VERSION "created by canmatrix"

NS_ :

BS_:

BU_: User ADM_PC_LL25 ADM_PC_BC25 ADM_PC_BP25 ADM_PC_BI25

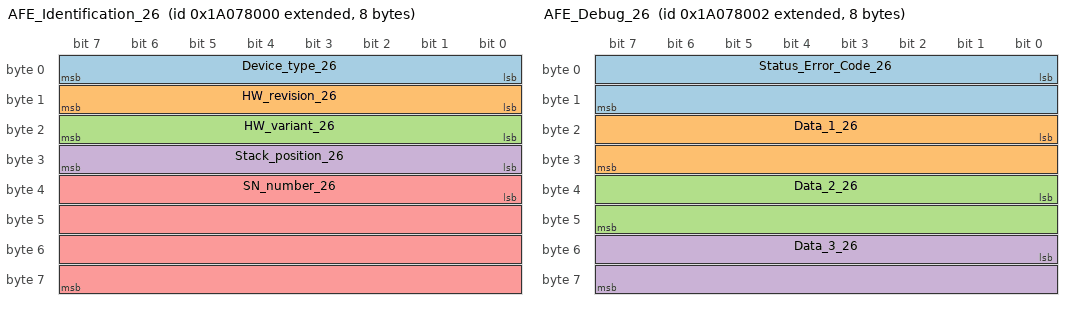
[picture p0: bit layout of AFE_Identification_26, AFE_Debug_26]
BO_ 2584182784 AFE_Identification_26: 8 ADM_PC_BP25
 SG_ Device_type_26 : 0|8@1+ (1,0) [0|255] "" Vector__XXX
 SG_ HW_revision_26 : 8|8@1+ (1,0) [0|255] "" Vector__XXX
 SG_ HW_variant_26 : 16|8@1+ (1,0) [0|255] "" Vector__XXX
 SG_ Stack_position_26 : 24|8@1+ (1,0) [0|255] "" Vector__XXX
 SG_ SN_number_26 : 32|32@1+ (1,0) [0|4294967295] "" Vector__XXX

BO_ 2584182785 AFE_FwInfo_26: 8 ADM_PC_BP25
 SG_ FW_info_mux_26 M : 56|8@1+ (1,0) [0|255] "" Vector__XXX
 SG_ FW_revision_0_26 m0 : 0|8@1+ (1,0) [0|255] "" Vector__XXX
 SG_ FW_revision_1_26 m0 : 8|8@1+ (1,0) [0|255] "" Vector__XXX
 SG_ FW_revision_2_26 m0 : 16|8@1+ (1,0) [0|255] "" Vector__XXX
 SG_ FW_revision_3_26 m0 : 24|8@1+ (1,0) [0|255] "" Vector__XXX
 SG_ FW_revision_4_26 m0 : 32|8@1+ (1,0) [0|255] "" Vector__XXX
 SG_ FW_revision_5_26 m0 : 40|8@1+ (1,0) [0|255] "" Vector__XXX
 SG_ FW_revision_6_26 m0 : 48|8@1+ (1,0) [0|255] "" Vector__XXX
 SG_ FW_revision_7_26 m1 : 0|8@1+ (1,0) [0|255] "" Vector__XXX
 SG_ FW_revision_8_26 m1 : 8|8@1+ (1,0) [0|255] "" Vector__XXX
 SG_ FW_revision_9_26 m1 : 16|8@1+ (1,0) [0|255] "" Vector__XXX
 SG_ FW_revision_10_26 m1 : 24|8@1+ (1,0) [0|255] "" Vector__XXX
 SG_ FW_revision_11_26 m1 : 32|8@1+ (1,0) [0|255] "" Vector__XXX
 SG_ FW_revision_12_26 m1 : 40|8@1+ (1,0) [0|255] "" Vector__XXX
 SG_ FW_revision_13_26 m1 : 48|8@1+ (1,0) [0|255] "" Vector__XXX
 SG_ FW_datecode_0_26 m2 : 0|8@1+ (1,0) [0|255] "" Vector__XXX
 SG_ FW_datecode_1_26 m2 : 8|8@1+ (1,0) [0|255] "" Vector__XXX
 SG_ FW_datecode_2_26 m2 : 16|8@1+ (1,0) [0|255] "" Vector__XXX
 SG_ FW_datecode_3_26 m2 : 24|8@1+ (1,0) [0|255] "" Vector__XXX
 SG_ FW_datecode_4_26 m2 : 32|8@1+ (1,0) [0|255] "" Vector__XXX
 SG_ FW_datecode_5_26 m2 : 40|8@1+ (1,0) [0|255] "" Vector__XXX
 SG_ FW_datecode_6_26 m2 : 48|8@1+ (1,0) [0|255] "" Vector__XXX
 SG_ FW_datecode_7_26 m3 : 0|8@1+ (1,0) [0|255] "" Vector__XXX
 SG_ FW_datecode_8_26 m3 : 8|8@1+ (1,0) [0|255] "" Vector__XXX
 SG_ FW_datecode_9_26 m3 : 16|8@1+ (1,0) [0|255] "" Vector__XXX
 SG_ FW_datecode_10_26 m3 : 24|8@1+ (1,0) [0|255] "" Vector__XXX
 SG_ FW_datecode_11_26 m3 : 32|8@1+ (1,0) [0|255] "" Vector__XXX
 SG_ FW_datecode_12_26 m3 : 40|8@1+ (1,0) [0|255] "" Vector__XXX
 SG_ FW_datecode_13_26 m3 : 48|8@1+ (1,0) [0|255] "" Vector__XXX

BO_ 2584182797 _AFE_Boot_FwInfo_26: 8 ADM_PC_BP25
 SG_ Boot_FW_info_mux_26 M : 56|8@1+ (1,0) [0|255] "" Vector__XXX
 SG_ FW_revision_0_26 m0 : 0|8@1+ (1,0) [0|255] "" Vector__XXX
 SG_ FW_revision_1_26 m0 : 8|8@1+ (1,0) [0|255] "" Vector__XXX
 SG_ FW_revision_2_26 m0 : 16|8@1+ (1,0) [0|255] "" Vector__XXX
 SG_ FW_revision_3_26 m0 : 24|8@1+ (1,0) [0|255] "" Vector__XXX
 SG_ FW_revision_4_26 m0 : 32|8@1+ (1,0) [0|255] "" Vector__XXX
 SG_ FW_revision_5_26 m0 : 40|8@1+ (1,0) [0|255] "" Vector__XXX
 SG_ FW_revision_6_26 m0 : 48|8@1+ (1,0) [0|255] "" Vector__XXX
 SG_ FW_revision_7_26 m1 : 0|8@1+ (1,0) [0|255] "" Vector__XXX
 SG_ FW_revision_8_26 m1 : 8|8@1+ (1,0) [0|255] "" Vector__XXX
 SG_ FW_revision_9_26 m1 : 16|8@1+ (1,0) [0|255] "" Vector__XXX
 SG_ FW_revision_10_26 m1 : 24|8@1+ (1,0) [0|255] "" Vector__XXX
 SG_ FW_revision_11_26 m1 : 32|8@1+ (1,0) [0|255] "" Vector__XXX
 SG_ FW_revision_12_26 m1 : 40|8@1+ (1,0) [0|255] "" Vector__XXX
 SG_ FW_revision_13_26 m1 : 48|8@1+ (1,0) [0|255] "" Vector__XXX
 SG_ FW_datecode_0_26 m2 : 0|8@1+ (1,0) [0|255] "" Vector__XXX
 SG_ FW_datecode_1_26 m2 : 8|8@1+ (1,0) [0|255] "" Vector__XXX
 SG_ FW_datecode_2_26 m2 : 16|8@1+ (1,0) [0|255] "" Vector__XXX
 SG_ FW_datecode_3_26 m2 : 24|8@1+ (1,0) [0|255] "" Vector__XXX
 SG_ FW_datecode_4_26 m2 : 32|8@1+ (1,0) [0|255] "" Vector__XXX
 SG_ FW_datecode_5_26 m2 : 40|8@1+ (1,0) [0|255] "" Vector__XXX
 SG_ FW_datecode_6_26 m2 : 48|8@1+ (1,0) [0|255] "" Vector__XXX
 SG_ FW_datecode_7_26 m3 : 0|8@1+ (1,0) [0|255] "" Vector__XXX
 SG_ FW_datecode_8_26 m3 : 8|8@1+ (1,0) [0|255] "" Vector__XXX
 SG_ FW_datecode_9_26 m3 : 16|8@1+ (1,0) [0|255] "" Vector__XXX
 SG_ FW_datecode_10_26 m3 : 24|8@1+ (1,0) [0|255] "" Vector__XXX
 SG_ FW_datecode_11_26 m3 : 32|8@1+ (1,0) [0|255] "" Vector__XXX
 SG_ FW_datecode_12_26 m3 : 40|8@1+ (1,0) [0|255] "" Vector__XXX
 SG_ FW_datecode_13_26 m3 : 48|8@1+ (1,0) [0|255] "" Vector__XXX

BO_ 2584182786 AFE_Debug_26: 8 ADM_PC_BP25
 SG_ Status_Error_Code_26 : 0|16@1+ (1,0) [0|65535] "" Vector__XXX
 SG_ Data_1_26 : 16|16@1+ (1,0) [0|65535] "" Vector__XXX
 SG_ Data_2_26 : 32|16@1+ (1,0) [0|65535] "" Vector__XXX
 SG_ Data_3_26 : 48|16@1+ (1,0) [0|65535] "" Vector__XXX

BO_ 2584182791 AFE_Status_26: 8 ADM_PC_BP25
 SG_ Running_26 : 0|1@1+ (1,0) [0|1] "" Vector__XXX
 SG_ PWM_26 : 1|1@1+ (1,0) [0|1] "" Vector__XXX
 SG_ Current_dc_loop_mode_26 : 2|1@1+ (1,0) [0|1] "" Vector__XXX
 SG_ Current_ac_loop_mode_26 : 3|1@1+ (1,0) [0|1] "" Vector__XXX
 SG_ Buck_26 : 5|1@1+ (1,0) [0|1] "" Vector__XXX
 SG_ Boost_26 : 6|1@1+ (1,0) [0|1] "" Vector__XXX
 SG_ Precharge_dc_buck_mode_26 : 7|1@1+ (1,0) [0|1] "" Vector__XXX
 SG_ Precharge_dc_boost_mode_26 : 8|1@1+ (1,0) [0|1] "" Vector__XXX
 SG_ Rectifier_3ph_26 : 9|1@1+ (1,0) [0|1] "" Vector__XXX
 SG_ Stack_mode_26 : 10|1@1+ (1,0) [0|1] "" Vector__XXX
 SG_ Master_26 : 11|1@1+ (1,0) [0|1] "" Vector__XXX
 SG_ Slave_26 : 12|1@1+ (1,0) [0|1] "" Vector__XXX
 SG_ Inverter_1ph_26 : 13|1@1+ (1,0) [0|1] "" Vector__XXX
 SG_ Boost_Neutral_26 : 14|1@1+ (1,0) [0|1] "" Vector__XXX
 SG_ Rectifier_1ph_26 : 15|1@1+ (1,0) [0|1] "" Vector__XXX
 SG_ Inverter_3ph_26 : 16|1@1+ (1,0) [0|1] "" Vector__XXX
 SG_ Ready_26 : 17|1@1+ (1,0) [0|1] "" Vector__XXX
 SG_ Inverter_1ph_Sync_26 : 18|1@1+ (1,0) [0|1] "" Vector__XXX
 SG_ Neutral_26 : 19|1@1+ (1,0) [0|1] "" Vector__XXX
 SG_ Rectifier_1ph_Buck_26 : 20|1@1+ (1,0) [0|1] "" Vector__XXX
 SG_ Inverter_1ph_Boost_26 : 21|1@1+ (1,0) [0|1] "" Vector__XXX
 SG_ Rectifier_distributed_26 : 22|1@1+ (1,0) [0|1] "" Vector__XXX
 SG_ MPPT_buck_26 : 23|1@1+ (1,0) [0|1] "" Vector__XXX
 SG_ MPPT_boost_26 : 24|1@1+ (1,0) [0|1] "" Vector__XXX
 SG_ Buck_2p_float_26 : 25|1@1+ (1,0) [0|1] "" Vector__XXX
 SG_ Inverter_1ph_Distributed_26 : 26|1@1+ (1,0) [0|1] "" Vector__XXX

BO_ 2584182790 AFE_Faults_26: 3 ADM_PC_BP25
 SG_ Protection_trip_internal_26 : 0|1@1+ (1,0) [0|1] "" Vector__XXX
 SG_ Protection_trip_external_26 : 1|1@1+ (1,0) [0|1] "" Vector__XXX
 SG_ Phase_U_overcurrent_26 : 2|1@1+ (1,0) [0|1] "" Vector__XXX
 SG_ Phase_U_overvoltage_26 : 3|1@1+ (1,0) [0|1] "" Vector__XXX
 SG_ Phase_U_undervoltage_26 : 4|1@1+ (1,0) [0|1] "" Vector__XXX
 SG_ Phase_V_overvoltage_26 : 5|1@1+ (1,0) [0|1] "" Vector__XXX
 SG_ Phase_V_undervoltage_26 : 6|1@1+ (1,0) [0|1] "" Vector__XXX
 SG_ Phase_V_overcurrent_26 : 7|1@1+ (1,0) [0|1] "" Vector__XXX
 SG_ Phase_W_overvoltage_26 : 8|1@1+ (1,0) [0|1] "" Vector__XXX
 SG_ Phase_W_undervoltage_26 : 9|1@1+ (1,0) [0|1] "" Vector__XXX
 SG_ Phase_W_overcurrent_26 : 10|1@1+ (1,0) [0|1] "" Vector__XXX
 SG_ DC_undervoltage_26 : 11|1@1+ (1,0) [0|1] "" Vector__XXX
 SG_ DC_overvoltage_26 : 12|1@1+ (1,0) [0|1] "" Vector__XXX
 SG_ MOSFET_overtemperature_26 : 13|1@1+ (1,0) [0|1] "" Vector__XXX
 SG_ Inductor_overtemperature_26 : 14|1@1+ (1,0) [0|1] "" Vector__XXX
 SG_ Keep_Alive_not_served_26 : 15|1@1+ (1,0) [0|1] "" Vector__XXX
 SG_ PLL_not_locked_26 : 16|1@1+ (1,0) [0|1] "" Vector__XXX
 SG_ NFO_26 : 20|1@1+ (1,0) [0|1] "" Vector__XXX
 SG_ Measurement_system_failure_26 : 21|1@1+ (1,0) [0|1] "" Vector__XXX
 SG_ EEPROM_failure_26 : 22|1@1+ (1,0) [0|1] "" Vector__XXX
 SG_ System_26 : 23|1@1+ (1,0) [0|1] "" Vector__XXX

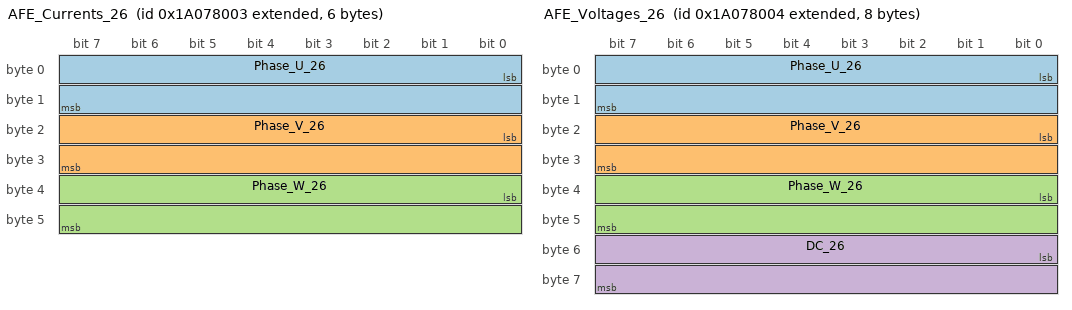
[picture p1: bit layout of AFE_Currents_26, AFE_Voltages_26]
BO_ 2584182787 AFE_Currents_26: 6 ADM_PC_BP25
 SG_ Phase_U_26 : 0|16@1- (0.01,0) [-327.68|327.67] "A" Vector__XXX
 SG_ Phase_V_26 : 16|16@1- (0.01,0) [-327.68|327.67] "A" Vector__XXX
 SG_ Phase_W_26 : 32|16@1- (0.01,0) [-327.68|327.67] "A" Vector__XXX

BO_ 2584182800 AFE_DC_Bus_current_26: 2 ADM_PC_BP25
 SG_ Bus_current_26 : 0|16@1- (0.01,0) [-327.68|327.67] "A" Vector__XXX

BO_ 2584182798 _AFE_Broadcast_26: 8 ADM_PC_BP25
 SG_ Diagnostics_Index_26 M : 56|8@1+ (1,0) [0|255] "" Vector__XXX
 SG_ Phase_U_26 m1 : 8|16@1- (0.01,0) [-327.68|327.67] "A" ADM_PC_BP25
 SG_ Phase_V_26 m1 : 24|16@1- (0.01,0) [-327.68|327.67] "A" ADM_PC_BP25
 SG_ Phase_W_26 m1 : 40|16@1- (0.01,0) [-327.68|327.67] "A" ADM_PC_BP25
 SG_ Stack_position_26 : 0|5@1+ (1,0) [0|31] "" ADM_PC_BP25
 SG_ Group_ID_26 : 5|3@1+ (1,0) [0|7] "" ADM_PC_BP25

BO_ 2584182788 AFE_Voltages_26: 8 ADM_PC_BP25
 SG_ Phase_U_26 : 0|16@1- (0.1,0) [-3276.8|3276.7] "V" Vector__XXX
 SG_ Phase_V_26 : 16|16@1- (0.1,0) [-3276.8|3276.7] "V" Vector__XXX
 SG_ Phase_W_26 : 32|16@1- (0.1,0) [-3276.8|3276.7] "V" Vector__XXX
 SG_ DC_26 : 48|16@1- (0.1,0) [-3276.8|3276.7] "V" Vector__XXX

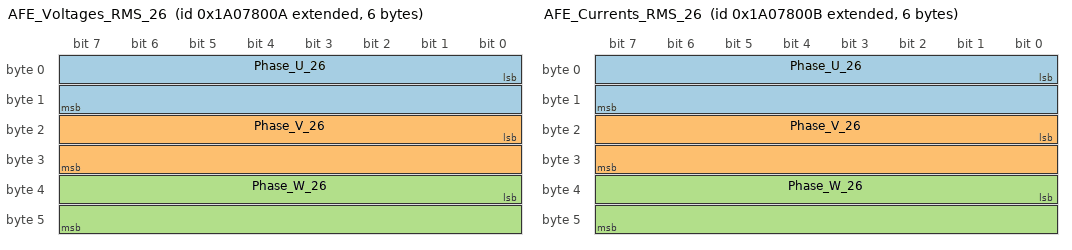
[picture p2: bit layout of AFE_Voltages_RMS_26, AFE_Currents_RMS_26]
BO_ 2584182794 AFE_Voltages_RMS_26: 6 ADM_PC_BP25
 SG_ Phase_U_26 : 0|16@1+ (0.1,0) [0|6553.5] "V" Vector__XXX
 SG_ Phase_V_26 : 16|16@1+ (0.1,0) [0|6553.5] "V" Vector__XXX
 SG_ Phase_W_26 : 32|16@1+ (0.1,0) [0|6553.5] "V" Vector__XXX

BO_ 2584182795 AFE_Currents_RMS_26: 6 ADM_PC_BP25
 SG_ Phase_U_26 : 0|16@1+ (0.01,0) [0.00|655.35] "A" Vector__XXX
 SG_ Phase_V_26 : 16|16@1+ (0.01,0) [0.00|655.35] "A" Vector__XXX
 SG_ Phase_W_26 : 32|16@1+ (0.01,0) [0.00|655.35] "A" Vector__XXX

BO_ 2584182796 AFE_Mains_26: 4 ADM_PC_BP25
 SG_ Frequency_26 : 0|16@1+ (0.01,0) [0.00|655.35] "Hz" Vector__XXX
 SG_ Phase_26 : 16|16@1- (0.1,0) [-3276.8|3276.7] "Deg." Vector__XXX

BO_ 2584182789 AFE_Temperatures_26: 4 ADM_PC_BP25
 SG_ Temp_Bridge_26 : 0|16@1- (0.01,0) [-327.68|327.67] "°C" Vector__XXX
 SG_ Temp_Inductors_26 : 16|16@1- (0.01,0) [-327.68|327.67] "°C" Vector__XXX

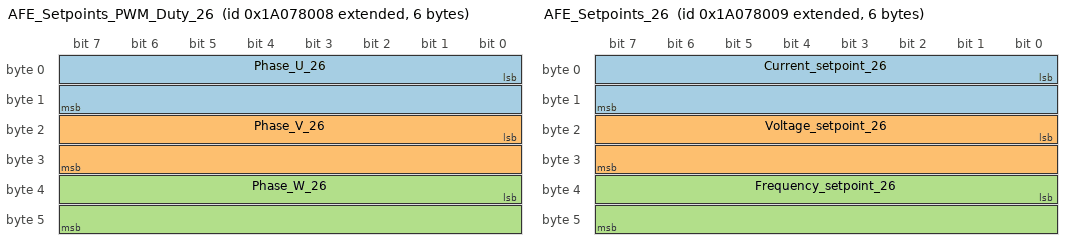
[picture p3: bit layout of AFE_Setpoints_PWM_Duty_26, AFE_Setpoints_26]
BO_ 2584182792 AFE_Setpoints_PWM_Duty_26: 6 ADM_PC_BP25
 SG_ Phase_U_26 : 0|16@1+ (0.001525902,0) [0E-009|99.999987570] "%" Vector__XXX
 SG_ Phase_V_26 : 16|16@1+ (0.001525902,0) [0E-009|99.999987570] "%" Vector__XXX
 SG_ Phase_W_26 : 32|16@1+ (0.001525902,0) [0E-009|99.999987570] "%" Vector__XXX

BO_ 2584182793 AFE_Setpoints_26: 6 ADM_PC_BP25
 SG_ Current_setpoint_26 : 0|16@1- (0.01,0) [-327.68|327.67] "A" Vector__XXX
 SG_ Voltage_setpoint_26 : 16|16@1+ (0.1,0) [0|6553.5] "V" Vector__XXX
 SG_ Frequency_setpoint_26 : 32|16@1+ (0.01,0) [0.00|655.35] "Hz" Vector__XXX

BO_ 2584150112 AFE_Keep_Alive_26: 1 User
 SG_ Keep_Alive_Enable_26 : 0|1@1+ (1,0) [0|1] "" ADM_PC_BP25

BO_ 2584150080 AFE_Mode_Control_26: 8 User
 SG_ Converter_ON_26 : 0|1@1+ (1,0) [0|1] "" ADM_PC_BP25
 SG_ PWM_ON_26 : 1|1@1+ (1,0) [0|1] "" ADM_PC_BP25
 SG_ DC_Current_feedback_ON_26 : 2|1@1+ (1,0) [0|1] "" ADM_PC_BP25
 SG_ AC_Current_feedback_ON_26 : 3|1@1+ (1,0) [0|1] "" ADM_PC_BP25
 SG_ Buck_ON_26 : 5|1@1+ (1,0) [0|1] "" ADM_PC_BP25
 SG_ Boost_ON_26 : 6|1@1+ (1,0) [0|1] "" ADM_PC_BP25
 SG_ Rectifier_3ph_ON_26 : 9|1@1+ (1,0) [0|1] "" ADM_PC_BP25
 SG_ Inverter_1ph_ON_26 : 10|1@1+ (1,0) [0|1] "" ADM_PC_BP25
 SG_ Rectifier_1ph_ON_26 : 11|1@1+ (1,0) [0|1] "" ADM_PC_BP25
 SG_ Boost_Neutral_ON_26 : 12|1@1+ (1,0) [0|1] "" ADM_PC_BP25
 SG_ Inverter_3ph_ON_26 : 13|1@1+ (1,0) [0|1] "" ADM_PC_BP25
 SG_ Inverter_1ph_Sync_ON_26 : 14|1@1+ (1,0) [0|1] "" ADM_PC_BP25
 SG_ Neutral_ON_26 : 15|1@1+ (1,0) [0|1] "" ADM_PC_BP25
 SG_ Rectifier_1ph_Buck_ON_26 : 16|1@1+ (1,0) [0|1] "" ADM_PC_BP25
 SG_ Inverter_1ph_Boost_ON_26 : 17|1@1+ (1,0) [0|1] "" ADM_PC_BP25
 SG_ Rectifier_Distributed_ON_26 : 18|1@1+ (1,0) [0|1] "" ADM_PC_BP25
 SG_ MPPT_buck_ON_26 : 19|1@1+ (1,0) [0|1] "" ADM_PC_BP25
 SG_ MPPT_boost_ON_26 : 20|1@1+ (1,0) [0|1] "" ADM_PC_BP25
 SG_ Buck_2p_float_ON_26 : 21|1@1+ (1,0) [0|1] "" ADM_PC_BP25
 SG_ Inverter_1ph_Distributed_ON_26 : 22|1@1+ (1,0) [0|1] "" ADM_PC_BP25

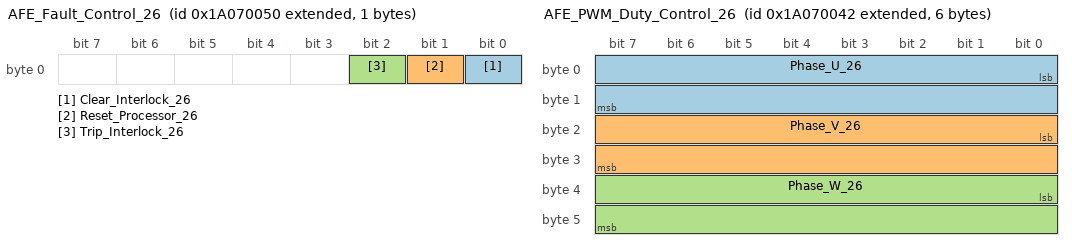
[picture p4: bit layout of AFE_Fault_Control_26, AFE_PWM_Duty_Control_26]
BO_ 2584150096 AFE_Fault_Control_26: 1 User
 SG_ Clear_Interlock_26 : 0|1@1+ (1,0) [0|1] "" ADM_PC_BP25
 SG_ Reset_Processor_26 : 1|1@1+ (1,0) [0|1] "" ADM_PC_BP25
 SG_ Trip_Interlock_26 : 2|1@1+ (1,0) [0|1] "" ADM_PC_BP25

BO_ 2584150081 AFE_Reactive_Current_Setpoint_Co: 2 User
 SG_ Reactive_current_setpoint_26 : 0|16@1- (0.01,0) [-150|150] "A" ADM_PC_BP25

BO_ 2584150082 AFE_PWM_Duty_Control_26: 6 User
 SG_ Phase_U_26 : 0|16@1+ (0.001525902,0) [0E-009|99.999987570] "%" ADM_PC_BP25
 SG_ Phase_V_26 : 16|16@1+ (0.001525902,0) [0E-009|99.999987570] "%" ADM_PC_BP25
 SG_ Phase_W_26 : 32|16@1+ (0.001525902,0) [0E-009|99.999987570] "%" ADM_PC_BP25

BO_ 2584150083 AFE_Current_Setpoint_Control_26: 2 User
 SG_ Current_setpoint_26 : 0|16@1- (0.01,0) [-150|150] "A" ADM_PC_BP25

BO_ 2584150084 AFE_Voltage_Setpoint_Control_26: 2 User
 SG_ Voltage_setpoint_26 : 0|16@1+ (0.1,0) [0|1500] "V" ADM_PC_BP25

BO_ 2584150088 AFE_Frequency_Setpoint_Control_2: 2 User
 SG_ Frequency_setpoint_26 : 0|16@1+ (0.01,0) [40|70] "Hz" ADM_PC_BP25

BO_ 2584150089 AFE_Phase_Setpoint_Control_26: 2 User
 SG_ Phase_setpoint_26 : 0|16@1+ (1,0) [0|360] "deg" ADM_PC_BP25

BO_ 2584150128 AFE_Rectifier_Setpoint_Control_2: 8 User
 SG_ Voltage_setpoint_2_26 : 0|16@1+ (0.1,0) [0|1500] "V" ADM_PC_BP25
 SG_ Current_setpoint_2_26 : 16|16@1- (0.01,0) [-150|150] "A" ADM_PC_BP25

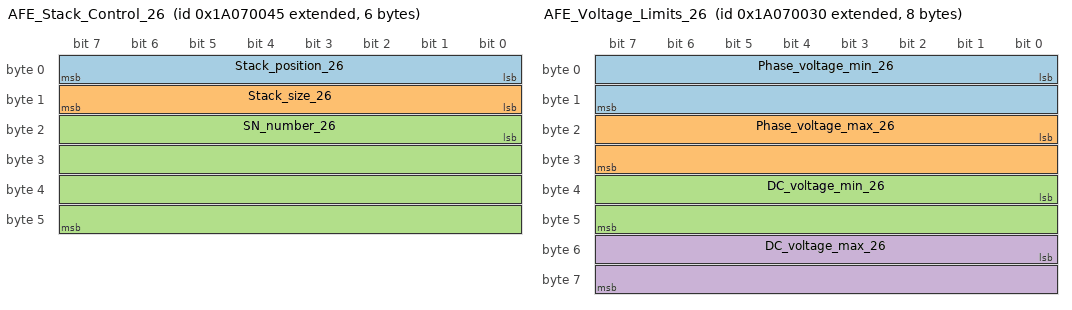
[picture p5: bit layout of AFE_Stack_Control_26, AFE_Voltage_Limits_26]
BO_ 2584150085 AFE_Stack_Control_26: 6 User
 SG_ Stack_position_26 : 0|8@1+ (1,0) [0|255] "" ADM_PC_BP25
 SG_ Stack_size_26 : 8|8@1+ (1,0) [0|255] "" ADM_PC_BP25
 SG_ SN_number_26 : 16|32@1+ (1,0) [0|4294967295] "" ADM_PC_BP25

BO_ 2584150064 AFE_Voltage_Limits_26: 8 User
 SG_ Phase_voltage_min_26 : 0|16@1- (0.1,0) [0|3276.7] "V" ADM_PC_BP25
 SG_ Phase_voltage_max_26 : 16|16@1- (0.1,0) [-3276.8|850] "V" ADM_PC_BP25
 SG_ DC_voltage_min_26 : 32|16@1- (0.1,0) [0|3276.7] "V" ADM_PC_BP25
 SG_ DC_voltage_max_26 : 48|16@1- (0.1,0) [-3276.8|850] "V" ADM_PC_BP25

BO_ 2584150065 AFE_Current_Limits_26: 4 User
 SG_ Phase_current_min_26 : 0|16@1- (0.01,0) [-60|60] "A" ADM_PC_BP25
 SG_ Phase_current_max_26 : 16|16@1- (0.01,0) [-60|60] "A" ADM_PC_BP25

BO_ 2584150092 AFE_Group_Control_26: 1 User
 SG_ Group_ID_26 : 0|8@1+ (1,0) [0|255] "" ADM_PC_BP25

BO_ 2584182799 AFE_Group_Info_26: 1 ADM_PC_BP25
 SG_ Group_ID_26 : 0|8@1+ (1,0) [0|255] "" Vector__XXX

BO_ 2584150113 AFE_System_Flags_Control_26: 8 User
 SG_ Factory_mode_26 : 0|1@1+ (1,0) [0|1] "" ADM_PC_BP25
 SG_ Silent_CAN_mode_26 : 1|1@1+ (1,0) [0|1] "" ADM_PC_BP25

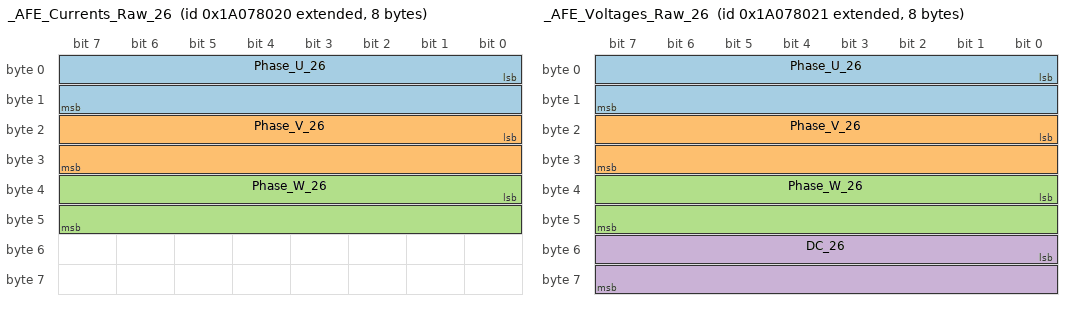
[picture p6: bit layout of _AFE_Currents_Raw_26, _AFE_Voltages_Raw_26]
BO_ 2584182816 _AFE_Currents_Raw_26: 8 ADM_PC_BP25
 SG_ Phase_U_26 : 0|16@1- (1,0) [-32768|32767] "" Vector__XXX
 SG_ Phase_V_26 : 16|16@1- (1,0) [-32768|32767] "" Vector__XXX
 SG_ Phase_W_26 : 32|16@1- (1,0) [-32768|32767] "" Vector__XXX

BO_ 2584182817 _AFE_Voltages_Raw_26: 8 ADM_PC_BP25
 SG_ Phase_U_26 : 0|16@1- (1,0) [-32768|32767] "" Vector__XXX
 SG_ Phase_V_26 : 16|16@1- (1,0) [-32768|32767] "" Vector__XXX
 SG_ Phase_W_26 : 32|16@1- (1,0) [-32768|32767] "" Vector__XXX
 SG_ DC_26 : 48|16@1- (1,0) [-32768|32767] "" Vector__XXX

BO_ 2584150090 _AFE_ADC_Calibration_Mode_26: 1 User
 SG_ Calibration_Index_26 M : 2|5@1+ (1,0) [0|31] "" Vector__XXX
 SG_ Current_U_26 m1 : 0|2@1+ (1,0) [0|3] "" ADM_PC_BP25
 SG_ Current_V_26 m2 : 0|2@1+ (1,0) [0|3] "" ADM_PC_BP25
 SG_ Current_W_26 m3 : 0|2@1+ (1,0) [0|3] "" ADM_PC_BP25
 SG_ Voltage_U_26 m4 : 0|2@1+ (1,0) [0|3] "" ADM_PC_BP25
 SG_ Voltage_V_26 m5 : 0|2@1+ (1,0) [0|3] "" ADM_PC_BP25
 SG_ Voltage_W_26 m6 : 0|2@1+ (1,0) [0|3] "" ADM_PC_BP25
 SG_ Voltage_DC_26 m7 : 0|2@1+ (1,0) [0|3] "" ADM_PC_BP25
 SG_ start_26 : 7|1@1+ (1,0) [0|1] "" ADM_PC_BP25

BO_ 2584150091 _AFE_ADC_Calibration_Setpoint_26: 3 User
 SG_ Calibration_Index_26 M : 16|5@1+ (1,0) [0|31] "" Vector__XXX
 SG_ Current_U_26 m1 : 0|16@1- (0.01,0) [-100|100] "A" ADM_PC_BP25
 SG_ Current_V_26 m2 : 0|16@1- (0.01,0) [-100|100] "A" ADM_PC_BP25
 SG_ Current_W_26 m3 : 0|16@1- (0.01,0) [-100|100] "A" ADM_PC_BP25
 SG_ Voltage_U_26 m4 : 0|16@1+ (0.1,0) [0|1500] "V" ADM_PC_BP25
 SG_ Voltage_V_26 m5 : 0|16@1+ (0.1,0) [0|1500] "V" ADM_PC_BP25
 SG_ Voltage_W_26 m6 : 0|16@1+ (0.1,0) [0|1500] "V" ADM_PC_BP25
 SG_ Voltage_DC_26 m7 : 0|16@1+ (0.1,0) [0|1500] "V" ADM_PC_BP25
 SG_ point_26 : 21|3@1+ (1,0) [0|7] "" ADM_PC_BP25

BO_ 2584150086 _AFE_Calibration_Offset_Update_2: 6 User
 SG_ Calibration_Index_26 M : 16|16@1+ (1,0) [0|65535] "" Vector__XXX
 SG_ Current_U_26 m0 : 0|16@1- (1,0) [-32768|32767] "ADC Counts" ADM_PC_BP25
 SG_ Current_V_26 m1 : 0|16@1- (1,0) [-32768|32767] "ADC Counts" ADM_PC_BP25
 SG_ Current_W_26 m2 : 0|16@1- (1,0) [-32768|32767] "ADC Counts" ADM_PC_BP25
 SG_ Voltage_U_26 m3 : 0|16@1- (1,0) [-32768|32767] "ADC Counts" ADM_PC_BP25
 SG_ Voltage_V_26 m4 : 0|16@1- (1,0) [-32768|32767] "ADC Counts" ADM_PC_BP25
 SG_ Voltage_W_26 m5 : 0|16@1- (1,0) [-32768|32767] "ADC Counts" ADM_PC_BP25
 SG_ Voltage_DC_26 m6 : 0|16@1- (1,0) [-32768|32767] "ADC Counts" ADM_PC_BP25
 SG_ CRC_26 : 32|16@1+ (1,0) [0|65535] "-" ADM_PC_BP25

BO_ 2584150087 _AFE_Calibration_Scale_Update_26: 6 User
 SG_ Calibration_Index_26 M : 16|16@1+ (1,0) [0|65535] "" Vector__XXX
 SG_ Current_U_26 m0 : 0|16@1- (0.0000152587890625,0) [-0.5000000000000000|0.4999847412109375] "scale = 1.0 + value" ADM_PC_BP25
 SG_ Current_V_26 m1 : 0|16@1- (0.0000152587890625,0) [-0.5000000000000000|0.4999847412109375] "scale = 1.0 + value" ADM_PC_BP25
 SG_ Current_W_26 m2 : 0|16@1- (0.0000152587890625,0) [-0.5000000000000000|0.4999847412109375] "scale = 1.0 + value" ADM_PC_BP25
 SG_ Voltage_U_26 m3 : 0|16@1- (0.0000152587890625,0) [-0.5000000000000000|0.4999847412109375] "scale = 1.0 + value" ADM_PC_BP25
 SG_ Voltage_V_26 m4 : 0|16@1- (0.0000152587890625,0) [-0.5000000000000000|0.4999847412109375] "scale = 1.0 + value" ADM_PC_BP25
 SG_ Voltage_W_26 m5 : 0|16@1- (0.0000152587890625,0) [-0.5000000000000000|0.4999847412109375] "scale = 1.0 + value" ADM_PC_BP25
 SG_ Voltage_DC_26 m6 : 0|16@1- (0.0000152587890625,0) [-0.5000000000000000|0.4999847412109375] "scale = 1.0 + value" ADM_PC_BP25
 SG_ CRC_26 : 32|16@1+ (1,0) [0|65535] "-" ADM_PC_BP25

BO_ 2584182865 _AFE_Calibration_Adc_Scale_26: 6 ADM_PC_BP25
 SG_ Adc_Index_26 M : 32|16@1+ (1,0) [0|65535] "" Vector__XXX
 SG_ Current_U_26 m0 : 0|32@1+ (1,0) [0|4294967295] "1 / adc_bins" User
 SG_ Current_V_26 m1 : 0|32@1+ (1,0) [0|4294967295] "1 / adc_bins" User
 SG_ Current_W_26 m2 : 0|32@1+ (1,0) [0|4294967295] "1 / adc_bins" User
 SG_ Voltage_U_26 m3 : 0|32@1+ (1,0) [0|4294967295] "1 / adc_bins" User
 SG_ Voltage_V_26 m4 : 0|32@1+ (1,0) [0|4294967295] "1 / adc_bins" User
 SG_ Voltage_W_26 m5 : 0|32@1+ (1,0) [0|4294967295] "1 / adc_bins" User
 SG_ Voltage_DC_26 m6 : 0|32@1+ (1,0) [0|4294967295] "1 / adc_bins" User

BO_ 2584182866 _AFE_Calibration_Adc_Fs_26: 6 ADM_PC_BP25
 SG_ Adc_Index_26 M : 32|16@1+ (1,0) [0|65535] "" Vector__XXX
 SG_ Current_U_26 m0 : 0|32@1+ (1,0) [0|4294967295] "Fullscale" User
 SG_ Current_V_26 m1 : 0|32@1+ (1,0) [0|4294967295] "Fullscale" User
 SG_ Current_W_26 m2 : 0|32@1+ (1,0) [0|4294967295] "Fullscale" User
 SG_ Voltage_U_26 m3 : 0|32@1+ (1,0) [0|4294967295] "Fullscale" User
 SG_ Voltage_V_26 m4 : 0|32@1+ (1,0) [0|4294967295] "Fullscale" User
 SG_ Voltage_W_26 m5 : 0|32@1+ (1,0) [0|4294967295] "Fullscale" User
 SG_ Voltage_DC_26 m6 : 0|32@1+ (1,0) [0|4294967295] "Fullscale" User

BO_ 2584182867 _AFE_Calibration_Adc_Offset_26: 4 ADM_PC_BP25
 SG_ Adc_Index_26 M : 16|16@1+ (1,0) [0|65535] "" Vector__XXX
 SG_ Current_U_26 m0 : 0|16@1- (1,0) [-32768|32767] "-" User
 SG_ Current_V_26 m1 : 0|16@1- (1,0) [-32768|32767] "-" User
 SG_ Current_W_26 m2 : 0|16@1- (1,0) [-32768|32767] "-" User
 SG_ Voltage_U_26 m3 : 0|16@1- (1,0) [-32768|32767] "-" User
 SG_ Voltage_V_26 m4 : 0|16@1- (1,0) [-32768|32767] "-" User
 SG_ Voltage_W_26 m5 : 0|16@1- (1,0) [-32768|32767] "-" User
 SG_ Voltage_DC_26 m6 : 0|16@1- (1,0) [-32768|32767] "-" User

BO_ 2584182868 _AFE_Calibration_Adc_Gain_26: 4 ADM_PC_BP25
 SG_ Adc_Index_26 M : 16|16@1+ (1,0) [0|65535] "" Vector__XXX
 SG_ Current_U_26 m0 : 0|16@1- (1,0) [-32768|32767] "-" User
 SG_ Current_V_26 m1 : 0|16@1- (1,0) [-32768|32767] "-" User
 SG_ Current_W_26 m2 : 0|16@1- (1,0) [-32768|32767] "-" User
 SG_ Voltage_U_26 m3 : 0|16@1- (1,0) [-32768|32767] "-" User
 SG_ Voltage_V_26 m4 : 0|16@1- (1,0) [-32768|32767] "-" User
 SG_ Voltage_W_26 m5 : 0|16@1- (1,0) [-32768|32767] "-" User
 SG_ Voltage_DC_26 m6 : 0|16@1- (1,0) [-32768|32767] "-" User

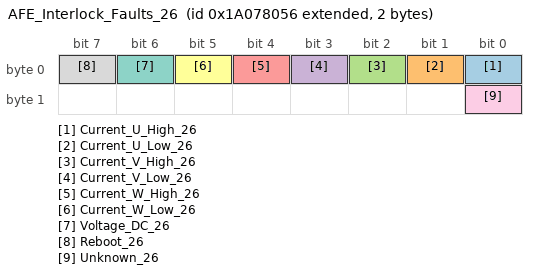
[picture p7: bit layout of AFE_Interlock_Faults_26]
BO_ 2584182870 AFE_Interlock_Faults_26: 2 ADM_PC_BP25
 SG_ Current_U_High_26 : 0|1@1+ (1,0) [0|1] "" Vector__XXX
 SG_ Current_U_Low_26 : 1|1@1+ (1,0) [0|1] "" Vector__XXX
 SG_ Current_V_High_26 : 2|1@1+ (1,0) [0|1] "" Vector__XXX
 SG_ Current_V_Low_26 : 3|1@1+ (1,0) [0|1] "" Vector__XXX
 SG_ Current_W_High_26 : 4|1@1+ (1,0) [0|1] "" Vector__XXX
 SG_ Current_W_Low_26 : 5|1@1+ (1,0) [0|1] "" Vector__XXX
 SG_ Voltage_DC_26 : 6|1@1+ (1,0) [0|1] "" Vector__XXX
 SG_ Reboot_26 : 7|1@1+ (1,0) [0|1] "" Vector__XXX
 SG_ Unknown_26 : 8|1@1+ (1,0) [0|1] "" Vector__XXX

BO_TX_BU_ 2584150080 : User,ADM_PC_LL25,ADM_PC_BC25,ADM_PC_BI25;
BO_TX_BU_ 2584150083 : User,ADM_PC_LL25,ADM_PC_BC25,ADM_PC_BI25;
BO_TX_BU_ 2584150084 : User,ADM_PC_LL25,ADM_PC_BC25,ADM_PC_BI25;
CM_ BO_ 2584182784  "Identification of the device";
CM_ BO_ 2584182785  "Git revision of the DSP firmware";
CM_ BO_ 2584182797  "Git revision of the bootloader firmware.";
CM_ BO_ 2584182786  "Values for debugging of HW/SW problems";
CM_ BO_ 2584182791  "Status bitfield";
CM_ BO_ 2584182790  "Fault bitfield";
CM_ BO_ 2584182787  "Current of phases U, V, W";
CM_ BO_ 2584182800  "Current of of the DC Bus";
CM_ BO_ 2584182798  "All AFEs will listen to this message";
CM_ BO_ 2584182795  "RMS Current of phases U, V, W";
CM_ BO_ 2584182796  "Three-Phase mains health (frequency, phase...)";
CM_ BO_ 2584182789  "Readouts of the module temperature sensors";
CM_ BO_ 2584182792  "Setpoints";
CM_ BO_ 2584182793  "Setpoints";
CM_ BO_ 2584150112  "Keep alive ping message. ";
CM_ BO_ 2584150080  "Operation Mode control: sets the converter operation mode";
CM_ BO_ 2584150096  "Fault Control: actions to clear faults and reset the system";
CM_ BO_ 2584150081  "Reactive power setpoint control.";
CM_ BO_ 2584150082  "PWM duty cycle control";
CM_ BO_ 2584150083  "Current setpoint control";
CM_ BO_ 2584150084  "Voltage setpoint control";
CM_ BO_ 2584150088  "Frequency setpoint control";
CM_ BO_ 2584150089  "Phase setpoint control";
CM_ BO_ 2584150128  "Additional voltage and current setpoints in single-phase rectifier and inverter control modes.";
CM_ BO_ 2584150085  "PFC stack control";
CM_ BO_ 2584150064  "Set the input and output voltage limits (minimum and maximum)";
CM_ BO_ 2584150065  "Set the output current limits (mminimum and maximum)";
CM_ BO_ 2584150092  "Set the Group ID of the device";
CM_ BO_ 2584182799  "Contains the Group ID of the device";
CM_ BO_ 2584150113  "Control the system flags";
CM_ BO_ 2584182816  "Current of phases A and B";
CM_ BO_ 2584182817  "Current of phases A and B";
CM_ BO_ 2584150090  "Automatic ADC calibration.";
CM_ BO_ 2584150091  "Setpoint for automatic ADC calibration.";
CM_ BO_ 2584150086  "Update of the calibration table for offsets.";
CM_ BO_ 2584150087  "Update of the calibration table for scales.";
CM_ BO_ 2584182865  "
                Adc scale (resolution) value of readouts.
            ";
CM_ BO_ 2584182866  "
                Adc fullscale value of readouts.
            ";
CM_ BO_ 2584182867  "
                Readout of ADC calibration data (offset) from EEPROM.
            ";
CM_ BO_ 2584182868  "
                Readout of ADC calibration data (gain) from EEPROM.
            ";
CM_ BO_ 2584182870  "Fault bitfield";

CM_ SG_ 2584182784 Device_type_26 "The device identification field, uniquely identifies the sender in the network";
CM_ SG_ 2584182784 HW_revision_26 "The hardware revision number";
CM_ SG_ 2584182784 HW_variant_26 "The DSP firmware revision number";
CM_ SG_ 2584182784 Stack_position_26 "Position of the module within the stack";
CM_ SG_ 2584182784 SN_number_26 "Unique module serial number";
CM_ SG_ 2584182785 FW_revision_0_26 "Character 0";
CM_ SG_ 2584182785 FW_revision_1_26 "Character 1";
CM_ SG_ 2584182785 FW_revision_2_26 "Character 2";
CM_ SG_ 2584182785 FW_revision_3_26 "Character 3";
CM_ SG_ 2584182785 FW_revision_4_26 "Character 3";
CM_ SG_ 2584182785 FW_revision_5_26 "Character 3";
CM_ SG_ 2584182785 FW_revision_6_26 "Character 3";
CM_ SG_ 2584182785 FW_revision_7_26 "Character 7";
CM_ SG_ 2584182785 FW_revision_8_26 "Character 8";
CM_ SG_ 2584182785 FW_revision_9_26 "Character 9";
CM_ SG_ 2584182785 FW_revision_10_26 "Character 10";
CM_ SG_ 2584182785 FW_revision_11_26 "Character 11";
CM_ SG_ 2584182785 FW_revision_12_26 "Character 12";
CM_ SG_ 2584182785 FW_revision_13_26 "Character 13";
CM_ SG_ 2584182785 FW_datecode_0_26 "Character 0";
CM_ SG_ 2584182785 FW_datecode_1_26 "Character 1";
CM_ SG_ 2584182785 FW_datecode_2_26 "Character 2";
CM_ SG_ 2584182785 FW_datecode_3_26 "Character 3";
CM_ SG_ 2584182785 FW_datecode_4_26 "Character 3";
CM_ SG_ 2584182785 FW_datecode_5_26 "Character 3";
CM_ SG_ 2584182785 FW_datecode_6_26 "Character 3";
CM_ SG_ 2584182785 FW_datecode_7_26 "Character 7";
CM_ SG_ 2584182785 FW_datecode_8_26 "Character 8";
CM_ SG_ 2584182785 FW_datecode_9_26 "Character 9";
CM_ SG_ 2584182785 FW_datecode_10_26 "Character 10";
CM_ SG_ 2584182785 FW_datecode_11_26 "Character 11";
CM_ SG_ 2584182785 FW_datecode_12_26 "Character 12";
CM_ SG_ 2584182785 FW_datecode_13_26 "Character 13";
CM_ SG_ 2584182797 FW_revision_0_26 "Character 0";
CM_ SG_ 2584182797 FW_revision_1_26 "Character 1";
CM_ SG_ 2584182797 FW_revision_2_26 "Character 2";
CM_ SG_ 2584182797 FW_revision_3_26 "Character 3";
CM_ SG_ 2584182797 FW_revision_4_26 "Character 3";
CM_ SG_ 2584182797 FW_revision_5_26 "Character 3";
CM_ SG_ 2584182797 FW_revision_6_26 "Character 3";
CM_ SG_ 2584182797 FW_revision_7_26 "Character 7";
CM_ SG_ 2584182797 FW_revision_8_26 "Character 8";
CM_ SG_ 2584182797 FW_revision_9_26 "Character 9";
CM_ SG_ 2584182797 FW_revision_10_26 "Character 10";
CM_ SG_ 2584182797 FW_revision_11_26 "Character 11";
CM_ SG_ 2584182797 FW_revision_12_26 "Character 12";
CM_ SG_ 2584182797 FW_revision_13_26 "Character 13";
CM_ SG_ 2584182797 FW_datecode_0_26 "Character 0";
CM_ SG_ 2584182797 FW_datecode_1_26 "Character 1";
CM_ SG_ 2584182797 FW_datecode_2_26 "Character 2";
CM_ SG_ 2584182797 FW_datecode_3_26 "Character 3";
CM_ SG_ 2584182797 FW_datecode_4_26 "Character 3";
CM_ SG_ 2584182797 FW_datecode_5_26 "Character 3";
CM_ SG_ 2584182797 FW_datecode_6_26 "Character 3";
CM_ SG_ 2584182797 FW_datecode_7_26 "Character 7";
CM_ SG_ 2584182797 FW_datecode_8_26 "Character 8";
CM_ SG_ 2584182797 FW_datecode_9_26 "Character 9";
CM_ SG_ 2584182797 FW_datecode_10_26 "Character 10";
CM_ SG_ 2584182797 FW_datecode_11_26 "Character 11";
CM_ SG_ 2584182797 FW_datecode_12_26 "Character 12";
CM_ SG_ 2584182797 FW_datecode_13_26 "Character 13";
CM_ SG_ 2584182786 Status_Error_Code_26 "Main status / error code as defined in errno/errno.h";
CM_ SG_ 2584182786 Data_1_26 "Additional information for the error/status";
CM_ SG_ 2584182786 Data_2_26 "Additional information for the error/status";
CM_ SG_ 2584182786 Data_3_26 "Additional information for the error/status";
CM_ SG_ 2584182791 Running_26 "Indicates if converter is running.";
CM_ SG_ 2584182791 PWM_26 "Indicates if converter is in PWM control mode.";
CM_ SG_ 2584182791 Current_dc_loop_mode_26 "Indicates if the current DC loop is enabled.";
CM_ SG_ 2584182791 Current_ac_loop_mode_26 "Indicates if the current AC loop is enabled.";
CM_ SG_ 2584182791 Buck_26 "Indicates if converter is in buck control mode.";
CM_ SG_ 2584182791 Boost_26 "Indicates if converter is in boost control mode.";
CM_ SG_ 2584182791 Precharge_dc_buck_mode_26 "Indicates if the precharge DC mode is enabled - buck direction.";
CM_ SG_ 2584182791 Precharge_dc_boost_mode_26 "Indicates if the precharge DC mode is enabled - boost direction.";
CM_ SG_ 2584182791 Rectifier_3ph_26 "Indicates if converter is in three-phase rectifier control mode.";
CM_ SG_ 2584182791 Stack_mode_26 "Indicates if converter is operating in stack mode.";
CM_ SG_ 2584182791 Master_26 "Indicates if converter is master in the stack.";
CM_ SG_ 2584182791 Slave_26 "Indicates if converter is slave in the stack.";
CM_ SG_ 2584182791 Inverter_1ph_26 "Indicates if converter is in single-phase inverter control mode.";
CM_ SG_ 2584182791 Boost_Neutral_26 "Indicates if converter is in boost control mode with neutral generation.";
CM_ SG_ 2584182791 Rectifier_1ph_26 "Indicates if converter is in single-phase rectifier control mode.";
CM_ SG_ 2584182791 Inverter_3ph_26 "Indicates if converter is in three-phase inverter control mode.";
CM_ SG_ 2584182791 Ready_26 "Indicates if converter is ready for operation.";
CM_ SG_ 2584182791 Inverter_1ph_Sync_26 "Single-phase inverter control mode with phase synchronization.";
CM_ SG_ 2584182791 Neutral_26 "Open-loop neutral generation.";
CM_ SG_ 2584182791 Rectifier_1ph_Buck_26 "Single-phase rectifier with buck on one leg.";
CM_ SG_ 2584182791 Inverter_1ph_Boost_26 "Single-phase inverter with boost on one leg.";
CM_ SG_ 2584182791 Rectifier_distributed_26 "Not available at the moment";
CM_ SG_ 2584182791 MPPT_buck_26 "Not available at the moment";
CM_ SG_ 2584182791 MPPT_boost_26 "Not available at the moment";
CM_ SG_ 2584182791 Buck_2p_float_26 "Buck in phases L1 and L2. Phase L3 is left floating (high impedance)";
CM_ SG_ 2584182791 Inverter_1ph_Distributed_26 "Single-phase inverter mode  distributed";
CM_ SG_ 2584182790 Protection_trip_internal_26 "This flagg is asserted if the interlock is open due to an internal fault condition (self-protection)";
CM_ SG_ 2584182790 Protection_trip_external_26 "This flag is asserted if the interlock is open due to an external condition received in the module.";
CM_ SG_ 2584182790 Phase_U_overcurrent_26 "Indicates an overcurrent event on Phase U. The overcurrent event is triggered when the measured phase current is over the programmed current limit.";
CM_ SG_ 2584182790 Phase_U_overvoltage_26 "Indicates an overvoltage event on Phase U. The overvoltage event is triggered when the measured phase voltage is over the programmed voltage limit.";
CM_ SG_ 2584182790 Phase_U_undervoltage_26 "Indicates an undervoltage event on Phase U. The overvoltage event is triggered when the measured phase voltage is over the programmed voltage limit.";
CM_ SG_ 2584182790 Phase_V_overvoltage_26 "Indicates an overvoltage event on Phase V. The overvoltage event is triggered when the measured phase voltage is over the programmed voltage limit.";
CM_ SG_ 2584182790 Phase_V_undervoltage_26 "Indicates an undervoltage event on Phase U. The overvoltage event is triggered when the measured phase voltage is over the programmed voltage limit.";
CM_ SG_ 2584182790 Phase_V_overcurrent_26 "Indicates an overcurrent event on Phase U. The overcurrent event is triggered when the measured phase current is over the programmed current limit.";
CM_ SG_ 2584182790 Phase_W_overvoltage_26 "Indicates an overvoltage event on Phase U. The overvoltage event is triggered when the measured phase voltage is over the programmed voltage limit.";
CM_ SG_ 2584182790 Phase_W_undervoltage_26 "Indicates an undervoltage event on Phase U. The overvoltage event is triggered when the measured phase voltage is over the programmed voltage limit.";
CM_ SG_ 2584182790 Phase_W_overcurrent_26 "Indicates an overcurrent event on Phase U. The overcurrent event is triggered when the measured phase current is over the programmed current limit.";
CM_ SG_ 2584182790 DC_undervoltage_26 "DC bus undervoltage condition. The undervoltage condition is asserted when the measured dc bus voltage is under the programmed voltage limit.";
CM_ SG_ 2584182790 DC_overvoltage_26 "DC bus overvoltage condition. The overvoltage condition is asserted when the measured dc bus voltage is over the programmed voltage limit.";
CM_ SG_ 2584182790 MOSFET_overtemperature_26 "This flag is asserted when the temperature of the MOSFET block is too high.";
CM_ SG_ 2584182790 Inductor_overtemperature_26 "This flag is asserted when the temperature of the inductor block is too high.";
CM_ SG_ 2584182790 Keep_Alive_not_served_26 "The Keep Alive feature is enabled but it was not served with the periodic message.";
CM_ SG_ 2584182790 PLL_not_locked_26 "Flag asserted when in rectifier modes, the PLL went out of lock condition";
CM_ SG_ 2584182790 Measurement_system_failure_26 "The voltages/currents measurement system is malfunctionning, and readouts are not guaranteed to be accurate.";
CM_ SG_ 2584182790 EEPROM_failure_26 "The configuration EEPROM failed to load or save the module configuration.";
CM_ SG_ 2584182787 Phase_U_26 "Phase current is the MOSFET loop current, in the branch U of the converter.";
CM_ SG_ 2584182787 Phase_V_26 "Phase current is the MOSFET loop current, in the branch V of the converter.";
CM_ SG_ 2584182787 Phase_W_26 "Phase current is the MOSFET loop current, in the branch W of the converter.";
CM_ SG_ 2584182800 Bus_current_26 "DC Bus current is possitive when current goes from input to output";
CM_ SG_ 2584182798 Phase_U_26 "Phase current is the MOSFET loop current, in the branch U of the converter.";
CM_ SG_ 2584182798 Phase_V_26 "Phase current is the MOSFET loop current, in the branch V of the converter.";
CM_ SG_ 2584182798 Phase_W_26 "Phase current is the MOSFET loop current, in the branch W of the converter.";
CM_ SG_ 2584182798 Stack_position_26 "Sender Stack position";
CM_ SG_ 2584182798 Group_ID_26 "Sender Group ID";
CM_ SG_ 2584182795 Phase_U_26 "RMS Phase current is the MOSFET loop current, in the branch U of the converter.";
CM_ SG_ 2584182795 Phase_V_26 "RMS Phase current is the MOSFET loop current, in the branch V of the converter.";
CM_ SG_ 2584182795 Phase_W_26 "RMS Phase current is the MOSFET loop current, in the branch W of the converter.";
CM_ SG_ 2584182796 Frequency_26 "Frequency of Three-Phase system";
CM_ SG_ 2584182796 Phase_26 "Phase of Three-Phase system";
CM_ SG_ 2584182789 Temp_Bridge_26 "Temperature of the MOSFET block";
CM_ SG_ 2584182789 Temp_Inductors_26 "Temperature of the inductors";
CM_ SG_ 2584182792 Phase_U_26 "The actual PWM duty cycle setpoint";
CM_ SG_ 2584182792 Phase_V_26 "The actual PWM duty cycle setpoint";
CM_ SG_ 2584182792 Phase_W_26 "The actual PWM duty cycle setpoint";
CM_ SG_ 2584182793 Current_setpoint_26 "The actual current setpoint";
CM_ SG_ 2584182793 Voltage_setpoint_26 "The actual voltage setpoint";
CM_ SG_ 2584182793 Frequency_setpoint_26 "The actual frequency setpoint";
CM_ SG_ 2584150112 Keep_Alive_Enable_26 "If set to 1, module will expect to receive this message every second repeatedly, or it will stop operation";
CM_ SG_ 2584150080 Converter_ON_26 "Enable the converter.";
CM_ SG_ 2584150080 PWM_ON_26 "Enable the PWM control mode.";
CM_ SG_ 2584150080 DC_Current_feedback_ON_26 "Enable the DC current loop";
CM_ SG_ 2584150080 AC_Current_feedback_ON_26 "Enable the AC current loop";
CM_ SG_ 2584150080 Buck_ON_26 "Enable the buck control mode.";
CM_ SG_ 2584150080 Boost_ON_26 "Enable the boost control mode.";
CM_ SG_ 2584150080 Rectifier_3ph_ON_26 "Enable the three-phase rectifier control mode.";
CM_ SG_ 2584150080 Inverter_1ph_ON_26 "Enable the single-phase inverter control mode.";
CM_ SG_ 2584150080 Rectifier_1ph_ON_26 "Enable the single-phase rectifier control mode.";
CM_ SG_ 2584150080 Boost_Neutral_ON_26 "Enable the boost control mode with neutral generation.";
CM_ SG_ 2584150080 Inverter_3ph_ON_26 "Enable the three-phase inverter control mode.";
CM_ SG_ 2584150080 Inverter_1ph_Sync_ON_26 "Single-phase inverter control mode with phase synchronization.";
CM_ SG_ 2584150080 Neutral_ON_26 "Open-loop neutral generation.";
CM_ SG_ 2584150080 Rectifier_1ph_Buck_ON_26 "Single-phase rectifier with buck on one leg.";
CM_ SG_ 2584150080 Inverter_1ph_Boost_ON_26 "Single-phase inverter with boost on one leg.";
CM_ SG_ 2584150080 Rectifier_Distributed_ON_26 "Single-phase (floating) distributed rectifier";
CM_ SG_ 2584150080 MPPT_buck_ON_26 "MPPT buck";
CM_ SG_ 2584150080 MPPT_boost_ON_26 "MPPT boost";
CM_ SG_ 2584150080 Buck_2p_float_ON_26 "Boost on L1 and L2. Floating L3 (high-impedance)";
CM_ SG_ 2584150080 Inverter_1ph_Distributed_ON_26 "Single-phase inverter mode distributed";
CM_ SG_ 2584150096 Clear_Interlock_26 "Clears the converter interlock";
CM_ SG_ 2584150096 Reset_Processor_26 "Reset the converter DSP";
CM_ SG_ 2584150096 Trip_Interlock_26 "Trip the inetrnal Interlock";
CM_ SG_ 2584150081 Reactive_current_setpoint_26 "This defines reactive current setpoint for 3-phase rectifier mode";
CM_ SG_ 2584150082 Phase_U_26 "The actual PWM duty cycle setpoint";
CM_ SG_ 2584150082 Phase_V_26 "The actual PWM duty cycle setpoint";
CM_ SG_ 2584150082 Phase_W_26 "The actual PWM duty cycle setpoint";
CM_ SG_ 2584150083 Current_setpoint_26 "Sets the output current setpoint. Active only when the current loop is enabled";
CM_ SG_ 2584150084 Voltage_setpoint_26 "Sets the output voltage setpoint. Active only when the voltage loop is enabled";
CM_ SG_ 2584150088 Frequency_setpoint_26 "Sets the frequency for single-phase and three-phase generator modes.";
CM_ SG_ 2584150089 Phase_setpoint_26 "Sets the phase for inverter control modes.";
CM_ SG_ 2584150085 Stack_position_26 "The converter position within the stack";
CM_ SG_ 2584150085 Stack_size_26 "How many PFC converters are in stack in total";
CM_ SG_ 2584150085 SN_number_26 "Unique module serial number";
CM_ SG_ 2584150064 Phase_voltage_min_26 "Minimum tolerated phase voltage";
CM_ SG_ 2584150064 Phase_voltage_max_26 "Maximum allowable phase voltage";
CM_ SG_ 2584150064 DC_voltage_min_26 "Minimum allowable dc voltage";
CM_ SG_ 2584150064 DC_voltage_max_26 "Maximum allowable dc voltage";
CM_ SG_ 2584150065 Phase_current_min_26 "Minimum allowable output current";
CM_ SG_ 2584150065 Phase_current_max_26 "Maximum allowable output current";
CM_ SG_ 2584150092 Group_ID_26 "Desired group ID for the device";
CM_ SG_ 2584182799 Group_ID_26 "Group ID of the device";
CM_ SG_ 2584150113 Factory_mode_26 "Customers MUST NOT USE this bit. If set to 1, module will enter in factory mode. ";
CM_ SG_ 2584150113 Silent_CAN_mode_26 "Customers MUST NOT USE this bit. If set to 1, module will enter in factory mode. ";
CM_ SG_ 2584150090 start_26 "Start automatic calibration. Multiplexer index must be 0!";
CM_ SG_ 2584150091 point_26 "Calibration point index.";
CM_ SG_ 2584150086 CRC_26 "Checksum of bytes 0 to 3, CRC-CCITT, corresponding to qChecksum (www.qt.io)";
CM_ SG_ 2584150087 CRC_26 "Checksum of bytes 0 to 3, CRC-CCITT, corresponding to qChecksum (www.qt.io)";
CM_ SG_ 2584182870 Current_U_High_26 "This flag is set if a hight current on U tripped the internal interlock";
CM_ SG_ 2584182870 Current_U_Low_26 "This flag is set if a low current on U tripped the internal interlock";
CM_ SG_ 2584182870 Current_V_High_26 "This flag is set if a hight current on V tripped the internal interlock";
CM_ SG_ 2584182870 Current_V_Low_26 "This flag is set if a low current on V tripped the internal interlock";
CM_ SG_ 2584182870 Current_W_High_26 "This flag is set if a hight current on W tripped the internal interlock";
CM_ SG_ 2584182870 Current_W_Low_26 "This flag is set if a low current on W tripped the internal interlock";
CM_ SG_ 2584182870 Voltage_DC_26 "This flag is set if a voltage on DC tripped the internal interlock";
CM_ SG_ 2584182870 Reboot_26 "This flag is set if a reboot tripped the internal interlock";
CM_ SG_ 2584182870 Unknown_26 "This flag the reason for the internal interlock is unknown";

BA_DEF_ BO_ "SystemMessageLongSymbol" STRING;

BA_ "SystemMessageLongSymbol" BO_ 2584150081 "AFE_Reactive_Current_Setpoint_Control_26";
BA_ "SystemMessageLongSymbol" BO_ 2584150088 "AFE_Frequency_Setpoint_Control_26";
BA_ "SystemMessageLongSymbol" BO_ 2584150128 "AFE_Rectifier_Setpoint_Control_26";
BA_ "SystemMessageLongSymbol" BO_ 2584150086 "_AFE_Calibration_Offset_Update_26";

VAL_ 2584182784 Device_type_26 7 "AFE";
VAL_ 2584182790 Protection_trip_internal_26 1 "fault";
VAL_ 2584182790 Protection_trip_external_26 1 "fault";
VAL_ 2584182790 Phase_U_overcurrent_26 1 "fault";
VAL_ 2584182790 Phase_U_overvoltage_26 1 "fault";
VAL_ 2584182790 Phase_U_undervoltage_26 1 "fault";
VAL_ 2584182790 Phase_V_overvoltage_26 1 "fault";
VAL_ 2584182790 Phase_V_undervoltage_26 1 "fault";
VAL_ 2584182790 Phase_V_overcurrent_26 1 "fault";
VAL_ 2584182790 Phase_W_overvoltage_26 1 "fault";
VAL_ 2584182790 Phase_W_undervoltage_26 1 "fault";
VAL_ 2584182790 Phase_W_overcurrent_26 1 "fault";
VAL_ 2584182790 DC_undervoltage_26 1 "fault";
VAL_ 2584182790 DC_overvoltage_26 1 "fault";
VAL_ 2584182790 MOSFET_overtemperature_26 1 "fault";
VAL_ 2584182790 Inductor_overtemperature_26 1 "fault";
VAL_ 2584182790 Keep_Alive_not_served_26 1 "fault";
VAL_ 2584182790 PLL_not_locked_26 1 "fault";
VAL_ 2584182790 NFO_26 1 "fault";
VAL_ 2584182790 Measurement_system_failure_26 1 "fault";
VAL_ 2584182790 EEPROM_failure_26 1 "fault";
VAL_ 2584182790 System_26 1 "fault";
VAL_ 2584182870 Current_U_High_26 1 "fault";
VAL_ 2584182870 Current_U_Low_26 1 "fault";
VAL_ 2584182870 Current_V_High_26 1 "fault";
VAL_ 2584182870 Current_V_Low_26 1 "fault";
VAL_ 2584182870 Current_W_High_26 1 "fault";
VAL_ 2584182870 Current_W_Low_26 1 "fault";
VAL_ 2584182870 Voltage_DC_26 1 "fault";
VAL_ 2584182870 Reboot_26 1 "fault";
VAL_ 2584182870 Unknown_26 1 "fault";
SIG_VALTYPE_ 2584182865 Current_U_26 : 1;
SIG_VALTYPE_ 2584182865 Current_V_26 : 1;
SIG_VALTYPE_ 2584182865 Current_W_26 : 1;
SIG_VALTYPE_ 2584182865 Voltage_U_26 : 1;
SIG_VALTYPE_ 2584182865 Voltage_V_26 : 1;
SIG_VALTYPE_ 2584182865 Voltage_W_26 : 1;
SIG_VALTYPE_ 2584182865 Voltage_DC_26 : 1;
SIG_VALTYPE_ 2584182866 Current_U_26 : 1;
SIG_VALTYPE_ 2584182866 Current_V_26 : 1;
SIG_VALTYPE_ 2584182866 Current_W_26 : 1;
SIG_VALTYPE_ 2584182866 Voltage_U_26 : 1;
SIG_VALTYPE_ 2584182866 Voltage_V_26 : 1;
SIG_VALTYPE_ 2584182866 Voltage_W_26 : 1;
SIG_VALTYPE_ 2584182866 Voltage_DC_26 : 1;
